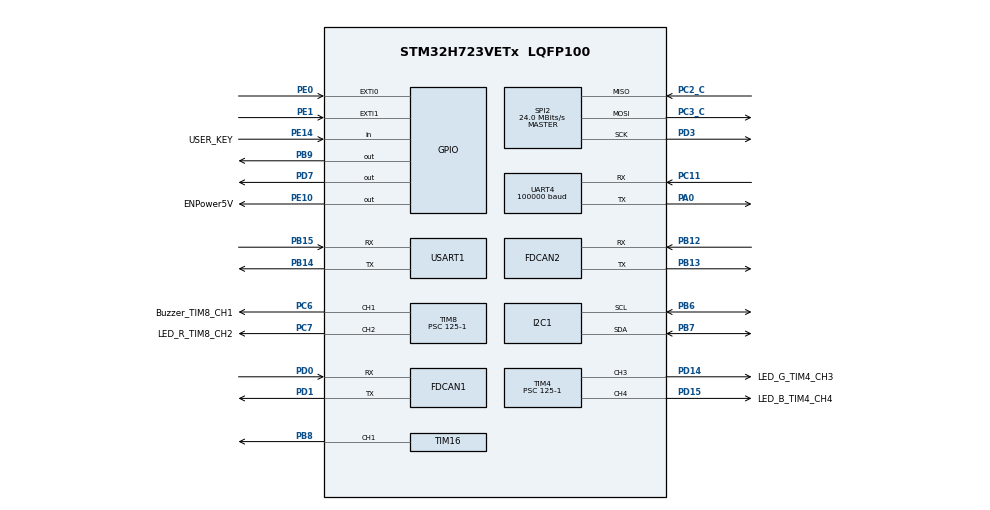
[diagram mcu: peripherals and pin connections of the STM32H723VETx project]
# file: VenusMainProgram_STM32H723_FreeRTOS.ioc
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FDCAN1.CalculateBaudRateNominal=1000000
FDCAN1.CalculateTimeBitNominal=1000
FDCAN1.CalculateTimeQuantumNominal=7.751937984496124
FDCAN1.ExtFiltersNbr=8
FDCAN1.NominalPrescaler=1
FDCAN1.NominalTimeSeg1=110
FDCAN1.NominalTimeSeg2=18
FDCAN1.RxBuffersNbr=2
FDCAN1.RxFifo0ElmtsNbr=2
FDCAN1.RxFifo1ElmtsNbr=2
FDCAN1.TxFifoQueueElmtsNbr=32
FDCAN2.CalculateBaudRateNominal=1000000
FDCAN2.CalculateTimeBitNominal=1000
FDCAN2.CalculateTimeQuantumNominal=7.751937984496124
FDCAN2.NominalPrescaler=1
FDCAN2.NominalTimeSeg1=110
FDCAN2.NominalTimeSeg2=18
FDCAN2.RxBuffersNbr=2
FDCAN2.RxFifo0ElmtsNbr=2
FDCAN2.RxFifo1ElmtsNbr=2
FDCAN2.TxFifoQueueElmtsNbr=2
FREERTOS.Tasks01=ReturnTask,8,256,StartReturnTask,As weak,NULL,Dynamic,NULL,NULL;SystemTask,40,128,StartSystemTask,As weak,NULL,Dynamic,NULL,NULL;MonitorTask,48,512,StartMonitorTask,As weak,NULL,Dynamic,NULL,NULL;ControlTask,32,256,StartControlTask,As weak,NULL,Dynamic,NULL,NULL;ChassisTask,24,256,StartChassisTask,As weak,NULL,Dynamic,NULL,NULL
FREERTOS.configENABLE_FPU=1
I2C1.Timing=0x20A0A3F6
Mcu.Family=STM32H7
Mcu.Name=STM32H723VETx
Mcu.Package=LQFP100
NVIC.FDCAN1_IT0_IRQn=true\:6\:0\:true\:false\:true\:true\:true\:true\:true
NVIC.FDCAN2_IT0_IRQn=true\:6\:0\:true\:false\:true\:true\:true\:true\:true
NVIC.PriorityGroup=NVIC_PRIORITYGROUP_4
NVIC.SPI2_IRQn=true\:5\:0\:false\:false\:true\:true\:true\:true\:true
NVIC.TIM6_DAC_IRQn=true\:15\:0\:false\:false\:true\:false\:false\:true\:true
NVIC.TimeBase=TIM6_DAC_IRQn
NVIC.TimeBaseIP=TIM6
NVIC.UART4_IRQn=true\:5\:0\:true\:false\:true\:true\:true\:true\:true
NVIC.USART1_IRQn=true\:6\:0\:true\:false\:true\:true\:true\:true\:true
PA0.Mode=Asynchronous
PA0.Signal=UART4_TX
PA13(JTMS/SWDIO).Mode=Serial_Wire
PA13(JTMS/SWDIO).Signal=DEBUG_JTMS-SWDIO
PA14(JTCK/SWCLK).Mode=Serial_Wire
PA14(JTCK/SWCLK).Signal=DEBUG_JTCK-SWCLK
PB12.Mode=FDCAN_Activate
PB12.Signal=FDCAN2_RX
PB13.Mode=FDCAN_Activate
PB13.Signal=FDCAN2_TX
PB14.Mode=Asynchronous
PB14.Signal=USART1_TX
PB15.Mode=Asynchronous
PB15.Signal=USART1_RX
PB6.Mode=I2C
PB6.Signal=I2C1_SCL
PB7.Mode=I2C
PB7.Signal=I2C1_SDA
PB8.Signal=S_TIM16_CH1
PB9.GPIO_Speed=GPIO_SPEED_FREQ_HIGH
PB9.Signal=GPIO_Output
PC11.Mode=Asynchronous
PC11.Signal=UART4_RX
PC14-OSC32_IN.Mode=LSE-External-Oscillator
PC14-OSC32_IN.Signal=RCC_OSC32_IN
PC15-OSC32_OUT.Mode=LSE-External-Oscillator
PC15-OSC32_OUT.Signal=RCC_OSC32_OUT
PC2_C.Mode=Full_Duplex_Master
PC2_C.Signal=SPI2_MISO
PC3_C.Mode=Full_Duplex_Master
PC3_C.Signal=SPI2_MOSI
PC6.GPIO_Label=Buzzer_TlM8_CH1
PC6.Signal=S_TIM8_CH1
PC7.GPIO_Label=LED_R_TIM8_CH2
PC7.Signal=S_TIM8_CH2
PD0.Mode=FDCAN_Activate
PD0.Signal=FDCAN1_RX
PD1.Mode=FDCAN_Activate
PD1.Signal=FDCAN1_TX
PD14.GPIO_Label=LED_G_TlM4_CH3
PD14.Signal=S_TIM4_CH3
PD15.GPIO_Label=LED_B_TlM4_CH4
PD15.Signal=S_TIM4_CH4
PD3.Mode=Full_Duplex_Master
PD3.Signal=SPI2_SCK
PD7.GPIO_Speed=GPIO_SPEED_FREQ_HIGH
PD7.Signal=GPIO_Output
PE0.Signal=GPXTI0
PE1.Signal=GPXTI1
PE10.GPIO_Label=ENPower5V
PE10.GPIO_PuPd=GPIO_NOPULL
PE10.GPIO_Speed=GPIO_SPEED_FREQ_HIGH
PE10.PinState=GPIO_PIN_RESET
PE10.Signal=GPIO_Output
PE14.GPIO_Label=USER_KEY
PE14.Signal=GPIO_Input
PH0-OSC_IN.Mode=HSE-External-Oscillator
PH0-OSC_IN.Signal=RCC_OSC_IN
PH1-OSC_OUT.Mode=HSE-External-Oscillator
PH1-OSC_OUT.Signal=RCC_OSC_OUT
ProjectManager.HeapSize=0x200
ProjectManager.StackSize=0x400
ProjectManager.TargetToolchain=MDK-ARM V5.32
RCC.ADCFreq_Value=129000000
RCC.APB1Freq_Value=125000000
RCC.APB2Freq_Value=125000000
RCC.APB3Freq_Value=125000000
RCC.APB4Freq_Value=125000000
RCC.CortexFreq_Value=500000000
RCC.D1PPRE=RCC_APB3_DIV2
RCC.D2PPRE1=RCC_APB1_DIV2
RCC.D2PPRE2=RCC_APB2_DIV2
RCC.D3PPRE=RCC_APB4_DIV2
RCC.DIVM1=4
RCC.DIVN1=31
RCC.DIVN3=96
RCC.DIVP1=1
RCC.DIVP3=4
RCC.DIVQ1=4
RCC.FDCANCLockSelection=RCC_FDCANCLKSOURCE_PLL2
RCC.HCLKFreq_Value=250000000
RCC.HPRE=RCC_HCLK_DIV2
RCC.PLL2FRACN=0
RCC.PLL3FRACN=0
RCC.PLLFRACN=2048
RCC.SPI123CLockSelection=RCC_SPI123CLKSOURCE_PLL3
RCC.SYSCLKFreq_VALUE=500000000
RCC.SYSCLKSource=RCC_SYSCLKSOURCE_PLLCLK
RCC.USBFreq_Value=125000000
SH.S_TIM16_CH1.0=TIM16_CH1,Output Compare1 CH1
SH.S_TIM4_CH3.0=TIM4_CH3,PWM Generation3 CH3
SH.S_TIM4_CH4.0=TIM4_CH4,PWM Generation4 CH4
SH.S_TIM8_CH1.0=TIM8_CH1,PWM Generation1 CH1
SH.S_TIM8_CH2.0=TIM8_CH2,PWM Generation2 CH2
SPI2.BaudRatePrescaler=SPI_BAUDRATEPRESCALER_2
SPI2.CalculateBaudRate=24.0 MBits/s
SPI2.DataSize=SPI_DATASIZE_8BIT
SPI2.Direction=SPI_DIRECTION_2LINES
SPI2.Mode=SPI_MODE_MASTER
SPI2.NSSPMode=SPI_NSS_PULSE_DISABLE
SPI2.VirtualType=VM_MASTER
TIM16.Channel=TIM_CHANNEL_1
TIM16.Period=100-1
TIM16.Prescaler=100-1
TIM4.Channel-PWM\ Generation3\ CH3=TIM_CHANNEL_3
TIM4.Channel-PWM\ Generation4\ CH4=TIM_CHANNEL_4
TIM4.Period=100-1
TIM4.Prescaler=125-1
TIM8.Channel-PWM\ Generation1\ CH1=TIM_CHANNEL_1
TIM8.Channel-PWM\ Generation2\ CH2=TIM_CHANNEL_2
TIM8.Period=100-1
TIM8.Prescaler=125-1
UART4.BaudRate=100000
UART4.Mode=MODE_RX
UART4.Parity=PARITY_EVEN
UART4.RxPinLevelInvertParam=UART_ADVFEATURE_RXINV_ENABLE
UART4.StopBits=UART_STOPBITS_2
USART1.VirtualMode-Asynchronous=VM_ASYNC
VP_FREERTOS_VS_CMSIS_V2.Mode=CMSIS_V2
VP_SYS_VS_tim6.Mode=TIM6
VP_TIM16_VS_ClockSourceINT.Mode=Enable_Timer
board=custom

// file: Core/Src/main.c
/* USER CODE BEGIN Header */
/**
  ******************************************************************************
  * @file           : main.c
  * @brief          : Main program body
  ******************************************************************************
  * @attention
  *
  * Copyright (c) 2024 STMicroelectronics.
  * All rights reserved.
  *
  * This software is licensed under terms that can be found in the LICENSE file
  * in the root directory of this software component.
  * If no LICENSE file comes with this software, it is provided AS-IS.
  *
  ******************************************************************************
  */
/* USER CODE END Header */
#include "main.h"
#include "cmsis_os.h"
#include "fdcan.h"
#include "i2c.h"
#include "spi.h"
#include "tim.h"
#include "usart.h"
#include "gpio.h"

/* USER CODE BEGIN Includes */

#include "Driver_drv.h" //驱动层头文件
#include "Device_dev.h" //设备层头文件

#include "Bsp_usart_fputc.h"

/* USER CODE END Includes */

void SystemClock_Config(void);
void PeriphCommonClock_Config(void);
void MX_FREERTOS_Init(void);

int main(void)
{

  /* MCU Configuration--------------------------------------------------------*/

  /* Reset of all peripherals, Initializes the Flash interface and the Systick. */
  HAL_Init();

  /* Configure the system clock */
  SystemClock_Config();

/* Configure the peripherals common clocks */
  PeriphCommonClock_Config();

  /* Initialize all configured peripherals */
  MX_GPIO_Init();
  MX_FDCAN1_Init();
  MX_FDCAN2_Init();
  MX_SPI2_Init();
  MX_TIM16_Init();
  MX_UART4_Init();
  MX_USART1_UART_Init();
  MX_TIM4_Init();
  MX_TIM8_Init();
  MX_I2C1_Init();
  /* USER CODE BEGIN 2 */

  /* 总外设初始化程序段 */

    Driver_Init(); //驱动层初始化
    Device_Init(); //设备层初始化

//    printf("----------Venus系统初始化完毕----------\r\n");
    printf("----------Venus System Initialization complete----------\r\n");

//    printf("----------IMU校准中----------\r\n");
//
    HAL_Delay(1000);

  /* USER CODE END 2 */

  /* Init scheduler */
  osKernelInitialize();

  /* Call init function for freertos objects (in cmsis_os2.c) */
  MX_FREERTOS_Init();

  /* Start scheduler */
  osKernelStart();

  /* We should never get here as control is now taken by the scheduler */

  /* Infinite loop */
  while (1)
  {

  }
}

void SystemClock_Config(void)
{
  RCC_OscInitTypeDef RCC_OscInitStruct = {0};
  RCC_ClkInitTypeDef RCC_ClkInitStruct = {0};

  /** Supply configuration update enable
  */
  HAL_PWREx_ConfigSupply(PWR_LDO_SUPPLY);

  /** Configure the main internal regulator output voltage
  */
  __HAL_PWR_VOLTAGESCALING_CONFIG(PWR_REGULATOR_VOLTAGE_SCALE0);

  while(!__HAL_PWR_GET_FLAG(PWR_FLAG_VOSRDY)) {}

  /** Initializes the RCC Oscillators according to the specified parameters
  * in the RCC_OscInitTypeDef structure.
  */
  RCC_OscInitStruct.OscillatorType = RCC_OSCILLATORTYPE_HSI;
  RCC_OscInitStruct.HSIState = RCC_HSI_DIV1;
  RCC_OscInitStruct.HSICalibrationValue = 64;
  RCC_OscInitStruct.PLL.PLLState = RCC_PLL_ON;
  RCC_OscInitStruct.PLL.PLLSource = RCC_PLLSOURCE_HSI;
  RCC_OscInitStruct.PLL.PLLM = 4;
  RCC_OscInitStruct.PLL.PLLN = 31;
  RCC_OscInitStruct.PLL.PLLP = 1;
  RCC_OscInitStruct.PLL.PLLQ = 4;
  RCC_OscInitStruct.PLL.PLLR = 2;
  RCC_OscInitStruct.PLL.PLLRGE = RCC_PLL1VCIRANGE_3;
  RCC_OscInitStruct.PLL.PLLVCOSEL = RCC_PLL1VCOWIDE;
  RCC_OscInitStruct.PLL.PLLFRACN = 2048;
  if (HAL_RCC_OscConfig(&RCC_OscInitStruct) != HAL_OK)
  {
    Error_Handler();
  }

  /** Initializes the CPU, AHB and APB buses clocks
  */
  RCC_ClkInitStruct.ClockType = RCC_CLOCKTYPE_HCLK|RCC_CLOCKTYPE_SYSCLK
                              |RCC_CLOCKTYPE_PCLK1|RCC_CLOCKTYPE_PCLK2
                              |RCC_CLOCKTYPE_D3PCLK1|RCC_CLOCKTYPE_D1PCLK1;
  RCC_ClkInitStruct.SYSCLKSource = RCC_SYSCLKSOURCE_PLLCLK;
  RCC_ClkInitStruct.SYSCLKDivider = RCC_SYSCLK_DIV1;
  RCC_ClkInitStruct.AHBCLKDivider = RCC_HCLK_DIV2;
  RCC_ClkInitStruct.APB3CLKDivider = RCC_APB3_DIV2;
  RCC_ClkInitStruct.APB1CLKDivider = RCC_APB1_DIV2;
  RCC_ClkInitStruct.APB2CLKDivider = RCC_APB2_DIV2;
  RCC_ClkInitStruct.APB4CLKDivider = RCC_APB4_DIV2;

  if (HAL_RCC_ClockConfig(&RCC_ClkInitStruct, FLASH_LATENCY_3) != HAL_OK)
  {
    Error_Handler();
  }
}

void PeriphCommonClock_Config(void)
{
  RCC_PeriphCLKInitTypeDef PeriphClkInitStruct = {0};

  /** Initializes the peripherals clock
  */
  PeriphClkInitStruct.PeriphClockSelection = RCC_PERIPHCLK_FDCAN;
  PeriphClkInitStruct.PLL2.PLL2M = 32;
  PeriphClkInitStruct.PLL2.PLL2N = 129;
  PeriphClkInitStruct.PLL2.PLL2P = 2;
  PeriphClkInitStruct.PLL2.PLL2Q = 2;
  PeriphClkInitStruct.PLL2.PLL2R = 2;
  PeriphClkInitStruct.PLL2.PLL2RGE = RCC_PLL2VCIRANGE_1;
  PeriphClkInitStruct.PLL2.PLL2VCOSEL = RCC_PLL2VCOWIDE;
  PeriphClkInitStruct.PLL2.PLL2FRACN = 0;
  PeriphClkInitStruct.FdcanClockSelection = RCC_FDCANCLKSOURCE_PLL2;
  if (HAL_RCCEx_PeriphCLKConfig(&PeriphClkInitStruct) != HAL_OK)
  {
    Error_Handler();
  }
}

void HAL_TIM_PeriodElapsedCallback(TIM_HandleTypeDef *htim)
{
  if (htim->Instance == TIM6) {
    HAL_IncTick();
  }
}

void Error_Handler(void)
{
  __disable_irq();
  while (1)
  {
  }
}

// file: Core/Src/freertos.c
/* USER CODE BEGIN Header */
/**
  ******************************************************************************
  * File Name          : freertos.c
  * Description        : Code for freertos applications
  ******************************************************************************
  * @attention
  *
  * Copyright (c) 2024 STMicroelectronics.
  * All rights reserved.
  *
  * This software is licensed under terms that can be found in the LICENSE file
  * in the root directory of this software component.
  * If no LICENSE file comes with this software, it is provided AS-IS.
  *
  ******************************************************************************
  */
/* USER CODE END Header */

#include "FreeRTOS.h"
#include "task.h"
#include "main.h"
#include "cmsis_os.h"

/* Definitions for ReturnTask */
osThreadId_t ReturnTaskHandle;
const osThreadAttr_t ReturnTask_attributes = {
  .name = "ReturnTask",
  .stack_size = 256 * 4,
  .priority = (osPriority_t) osPriorityLow,
};
/* Definitions for SystemTask */
osThreadId_t SystemTaskHandle;
const osThreadAttr_t SystemTask_attributes = {
  .name = "SystemTask",
  .stack_size = 128 * 4,
  .priority = (osPriority_t) osPriorityHigh,
};
/* Definitions for MonitorTask */
osThreadId_t MonitorTaskHandle;
const osThreadAttr_t MonitorTask_attributes = {
  .name = "MonitorTask",
  .stack_size = 512 * 4,
  .priority = (osPriority_t) osPriorityRealtime,
};
/* Definitions for ControlTask */
osThreadId_t ControlTaskHandle;
const osThreadAttr_t ControlTask_attributes = {
  .name = "ControlTask",
  .stack_size = 256 * 4,
  .priority = (osPriority_t) osPriorityAboveNormal,
};
/* Definitions for ChassisTask */
osThreadId_t ChassisTaskHandle;
const osThreadAttr_t ChassisTask_attributes = {
  .name = "ChassisTask",
  .stack_size = 256 * 4,
  .priority = (osPriority_t) osPriorityNormal,
};

void StartReturnTask(void *argument);
void StartSystemTask(void *argument);
void StartMonitorTask(void *argument);
void StartControlTask(void *argument);
void StartChassisTask(void *argument);

void MX_FREERTOS_Init(void); /* (MISRA C 2004 rule 8.1) */

void MX_FREERTOS_Init(void) {

  /* Create the thread(s) */
  /* creation of ReturnTask */
  ReturnTaskHandle = osThreadNew(StartReturnTask, NULL, &ReturnTask_attributes);

  /* creation of SystemTask */
  SystemTaskHandle = osThreadNew(StartSystemTask, NULL, &SystemTask_attributes);

  /* creation of MonitorTask */
  MonitorTaskHandle = osThreadNew(StartMonitorTask, NULL, &MonitorTask_attributes);

  /* creation of ControlTask */
  ControlTaskHandle = osThreadNew(StartControlTask, NULL, &ControlTask_attributes);

  /* creation of ChassisTask */
  ChassisTaskHandle = osThreadNew(StartChassisTask, NULL, &ChassisTask_attributes);

}

__weak void StartReturnTask(void *argument)
{
  for(;;)
  {
    osDelay(1);
  }
}

__weak void StartSystemTask(void *argument)
{
  for(;;)
  {
    osDelay(1);
  }
}

__weak void StartMonitorTask(void *argument)
{
  for(;;)
  {
    osDelay(1);
  }
}

__weak void StartControlTask(void *argument)
{
  for(;;)
  {
    osDelay(1);
  }
}

__weak void StartChassisTask(void *argument)
{
  for(;;)
  {
    osDelay(1);
  }
}
